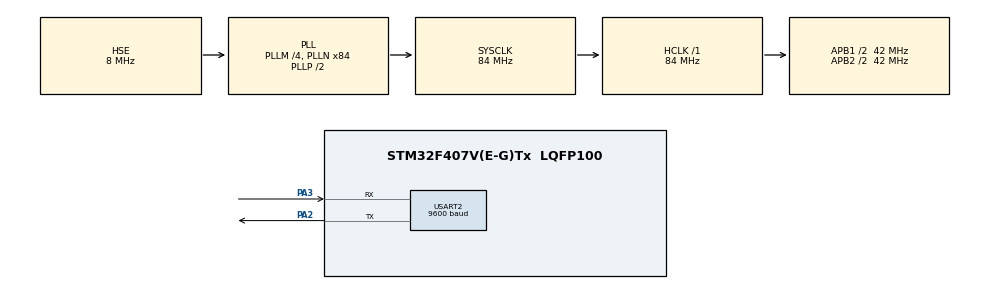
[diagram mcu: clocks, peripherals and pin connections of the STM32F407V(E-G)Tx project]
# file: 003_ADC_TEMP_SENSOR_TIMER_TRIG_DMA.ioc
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ADC1.Channel-0\#ChannelRegularConversion=ADC_CHANNEL_TEMPSENSOR
ADC1.Channel-4\#ChannelRegularConversion=ADC_CHANNEL_TEMPSENSOR
ADC1.Channel-5\#ChannelRegularConversion=ADC_CHANNEL_TEMPSENSOR
ADC1.ClockPrescaler=ADC_CLOCK_SYNC_PCLK_DIV8
ADC1.DMAContinuousRequests=ENABLE
ADC1.EOCSelection=ADC_EOC_SINGLE_CONV
ADC1.ExternalTrigConv=ADC_EXTERNALTRIGCONV_T8_TRGO
ADC1.InjNumberOfConversion=0
ADC1.NbrOfConversion=3
ADC1.NbrOfConversionFlag=1
ADC1.Rank-0\#ChannelRegularConversion=1
ADC1.Rank-4\#ChannelRegularConversion=2
ADC1.Rank-5\#ChannelRegularConversion=3
ADC1.SamplingTime-0\#ChannelRegularConversion=ADC_SAMPLETIME_480CYCLES
ADC1.SamplingTime-4\#ChannelRegularConversion=ADC_SAMPLETIME_480CYCLES
ADC1.SamplingTime-5\#ChannelRegularConversion=ADC_SAMPLETIME_480CYCLES
ADC1.master=1
Dma.ADC1.0.Direction=DMA_PERIPH_TO_MEMORY
Dma.ADC1.0.FIFOMode=DMA_FIFOMODE_DISABLE
Dma.ADC1.0.Instance=DMA2_Stream0
Dma.ADC1.0.MemDataAlignment=DMA_MDATAALIGN_HALFWORD
Dma.ADC1.0.MemInc=DMA_MINC_ENABLE
Dma.ADC1.0.Mode=DMA_CIRCULAR
Dma.ADC1.0.PeriphDataAlignment=DMA_PDATAALIGN_HALFWORD
Dma.ADC1.0.PeriphInc=DMA_PINC_DISABLE
Dma.ADC1.0.Priority=DMA_PRIORITY_LOW
Dma.Request0=ADC1
Mcu.Family=STM32F4
Mcu.Name=STM32F407V(E-G)Tx
Mcu.Package=LQFP100
NVIC.DMA2_Stream0_IRQn=true\:0\:0\:false\:false\:true\:false\:true
NVIC.PriorityGroup=NVIC_PRIORITYGROUP_0
NVIC.TIM8_UP_TIM13_IRQn=true\:0\:0\:false\:false\:true\:true\:true
PA2.Mode=Asynchronous
PA2.Signal=USART2_TX
PA3.Mode=Asynchronous
PA3.Signal=USART2_RX
PH0-OSC_IN.Mode=HSE-External-Oscillator
PH0-OSC_IN.Signal=RCC_OSC_IN
PH1-OSC_OUT.Mode=HSE-External-Oscillator
PH1-OSC_OUT.Signal=RCC_OSC_OUT
ProjectManager.HeapSize=0x200
ProjectManager.StackSize=0x400
ProjectManager.TargetToolchain=STM32CubeIDE
RCC.48MHZClocksFreq_Value=24000000
RCC.AHBFreq_Value=84000000
RCC.APB1CLKDivider=RCC_HCLK_DIV2
RCC.APB1Freq_Value=42000000
RCC.APB1TimFreq_Value=84000000
RCC.APB2CLKDivider=RCC_HCLK_DIV2
RCC.APB2Freq_Value=42000000
RCC.APB2TimFreq_Value=84000000
RCC.CortexFreq_Value=84000000
RCC.HCLKFreq_Value=84000000
RCC.HSE_VALUE=8000000
RCC.HSI_VALUE=16000000
RCC.PLLM=4
RCC.PLLN=84
RCC.PLLQ=7
RCC.PLLSourceVirtual=RCC_PLLSOURCE_HSE
RCC.SYSCLKFreq_VALUE=84000000
RCC.SYSCLKSource=RCC_SYSCLKSOURCE_PLLCLK
RCC.VCOOutputFreq_Value=168000000
TIM8.Period=1999
TIM8.Prescaler=41999
TIM8.TIM_MasterOutputTrigger=TIM_TRGO_UPDATE
TIM8.TIM_MasterSlaveMode=TIM_MASTERSLAVEMODE_ENABLE
USART2.BaudRate=9600
USART2.VirtualMode=VM_ASYNC
VP_ADC1_TempSens_Input.Mode=IN-TempSens
VP_TIM8_VS_ClockSourceINT.Mode=Internal
board=STM32F407G-DISC1

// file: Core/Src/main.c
/* USER CODE BEGIN Header */
/**
  ******************************************************************************
  * @file           : main.c
  * @brief          : Main program body
  ******************************************************************************
  * @attention
  *
  * Copyright (c) 2022 STMicroelectronics.
  * All rights reserved.
  *
  * This software is licensed under terms that can be found in the LICENSE file
  * in the root directory of this software component.
  * If no LICENSE file comes with this software, it is provided AS-IS.
  *
  ******************************************************************************
  */
/* USER CODE END Header */
#include "main.h"
#include <string.h>
#include <stdio.h>

ADC_HandleTypeDef hadc1;
DMA_HandleTypeDef hdma_adc1;

TIM_HandleTypeDef htim8;

UART_HandleTypeDef huart2;

/* USER CODE BEGIN PV */
volatile uint8_t convCompleted = 0;
uint16_t rawValues[3];
/* USER CODE END PV */

void SystemClock_Config(void);
static void MX_GPIO_Init(void);
static void MX_DMA_Init(void);
static void MX_ADC1_Init(void);
static void MX_TIM8_Init(void);
static void MX_USART2_UART_Init(void);

int main(void)
{
  /* USER CODE BEGIN 1 */
	char msg[35];

	  float temp;
  /* USER CODE END 1 */

  /* MCU Configuration--------------------------------------------------------*/

  /* Reset of all peripherals, Initializes the Flash interface and the Systick. */
  HAL_Init();

  /* Configure the system clock */
  SystemClock_Config();

  /* Initialize all configured peripherals */
  MX_GPIO_Init();
  MX_DMA_Init();
  MX_ADC1_Init();
  MX_TIM8_Init();
  MX_USART2_UART_Init();
  /* USER CODE BEGIN 2 */
  HAL_TIM_Base_Start(&htim8);
    HAL_ADC_Start_DMA(&hadc1, (uint32_t*)rawValues, 3);
  /* USER CODE END 2 */

  /* Infinite loop */
  while (1)
  {

    /* USER CODE BEGIN 3 */
	  while(!convCompleted)
	  {

	  }

	       for(uint8_t i = 0; i < hadc1.Init.NbrOfConversion; i++) {
	    	   temp = (((float)rawValues[i]) / 4095) * 3000;
	    	   	temp = ((temp - 760.0) / 2.5) + 25;

	        sprintf(msg, "rawValue %d: %hu\r\n", i, rawValues[i]);
	        HAL_UART_Transmit(&huart2, (uint8_t*) msg, strlen(msg), HAL_MAX_DELAY);

	        sprintf(msg, "Temperature %d: %.3f\r\n",i,  temp);
	        HAL_UART_Transmit(&huart2, (uint8_t*) msg, strlen(msg), HAL_MAX_DELAY);
	      }
	      convCompleted = 0;
  }
  /* USER CODE END 3 */
}

void SystemClock_Config(void)
{
  RCC_OscInitTypeDef RCC_OscInitStruct = {0};
  RCC_ClkInitTypeDef RCC_ClkInitStruct = {0};

  /** Configure the main internal regulator output voltage
  */
  __HAL_RCC_PWR_CLK_ENABLE();
  __HAL_PWR_VOLTAGESCALING_CONFIG(PWR_REGULATOR_VOLTAGE_SCALE1);
  /** Initializes the RCC Oscillators according to the specified parameters
  * in the RCC_OscInitTypeDef structure.
  */
  RCC_OscInitStruct.OscillatorType = RCC_OSCILLATORTYPE_HSE;
  RCC_OscInitStruct.HSEState = RCC_HSE_ON;
  RCC_OscInitStruct.PLL.PLLState = RCC_PLL_ON;
  RCC_OscInitStruct.PLL.PLLSource = RCC_PLLSOURCE_HSE;
  RCC_OscInitStruct.PLL.PLLM = 4;
  RCC_OscInitStruct.PLL.PLLN = 84;
  RCC_OscInitStruct.PLL.PLLP = RCC_PLLP_DIV2;
  RCC_OscInitStruct.PLL.PLLQ = 7;
  if (HAL_RCC_OscConfig(&RCC_OscInitStruct) != HAL_OK)
  {
    Error_Handler();
  }
  /** Initializes the CPU, AHB and APB buses clocks
  */
  RCC_ClkInitStruct.ClockType = RCC_CLOCKTYPE_HCLK|RCC_CLOCKTYPE_SYSCLK
                              |RCC_CLOCKTYPE_PCLK1|RCC_CLOCKTYPE_PCLK2;
  RCC_ClkInitStruct.SYSCLKSource = RCC_SYSCLKSOURCE_PLLCLK;
  RCC_ClkInitStruct.AHBCLKDivider = RCC_SYSCLK_DIV1;
  RCC_ClkInitStruct.APB1CLKDivider = RCC_HCLK_DIV2;
  RCC_ClkInitStruct.APB2CLKDivider = RCC_HCLK_DIV2;

  if (HAL_RCC_ClockConfig(&RCC_ClkInitStruct, FLASH_LATENCY_2) != HAL_OK)
  {
    Error_Handler();
  }
}

static void MX_ADC1_Init(void)
{

  ADC_ChannelConfTypeDef sConfig = {0};

  /** Configure the global features of the ADC (Clock, Resolution, Data Alignment and number of conversion)
  */
  hadc1.Instance = ADC1;
  hadc1.Init.ClockPrescaler = ADC_CLOCK_SYNC_PCLK_DIV8;
  hadc1.Init.Resolution = ADC_RESOLUTION_12B;
  hadc1.Init.ScanConvMode = ENABLE;
  hadc1.Init.ContinuousConvMode = DISABLE;
  hadc1.Init.DiscontinuousConvMode = DISABLE;
  hadc1.Init.ExternalTrigConvEdge = ADC_EXTERNALTRIGCONVEDGE_RISING;
  hadc1.Init.ExternalTrigConv = ADC_EXTERNALTRIGCONV_T8_TRGO;
  hadc1.Init.DataAlign = ADC_DATAALIGN_RIGHT;
  hadc1.Init.NbrOfConversion = 3;
  hadc1.Init.DMAContinuousRequests = ENABLE;
  hadc1.Init.EOCSelection = ADC_EOC_SINGLE_CONV;
  if (HAL_ADC_Init(&hadc1) != HAL_OK)
  {
    Error_Handler();
  }
  /** Configure for the selected ADC regular channel its corresponding rank in the sequencer and its sample time.
  */
  sConfig.Channel = ADC_CHANNEL_TEMPSENSOR;
  sConfig.Rank = 1;
  sConfig.SamplingTime = ADC_SAMPLETIME_480CYCLES;
  if (HAL_ADC_ConfigChannel(&hadc1, &sConfig) != HAL_OK)
  {
    Error_Handler();
  }
  /** Configure for the selected ADC regular channel its corresponding rank in the sequencer and its sample time.
  */
  sConfig.Rank = 2;
  if (HAL_ADC_ConfigChannel(&hadc1, &sConfig) != HAL_OK)
  {
    Error_Handler();
  }
  /** Configure for the selected ADC regular channel its corresponding rank in the sequencer and its sample time.
  */
  sConfig.Rank = 3;
  if (HAL_ADC_ConfigChannel(&hadc1, &sConfig) != HAL_OK)
  {
    Error_Handler();
  }

}

static void MX_TIM8_Init(void)
{

  TIM_ClockConfigTypeDef sClockSourceConfig = {0};
  TIM_MasterConfigTypeDef sMasterConfig = {0};

  htim8.Instance = TIM8;
  htim8.Init.Prescaler = 41999;
  htim8.Init.CounterMode = TIM_COUNTERMODE_UP;
  htim8.Init.Period = 1999;
  htim8.Init.ClockDivision = TIM_CLOCKDIVISION_DIV1;
  htim8.Init.RepetitionCounter = 0;
  htim8.Init.AutoReloadPreload = TIM_AUTORELOAD_PRELOAD_DISABLE;
  if (HAL_TIM_Base_Init(&htim8) != HAL_OK)
  {
    Error_Handler();
  }
  sClockSourceConfig.ClockSource = TIM_CLOCKSOURCE_INTERNAL;
  if (HAL_TIM_ConfigClockSource(&htim8, &sClockSourceConfig) != HAL_OK)
  {
    Error_Handler();
  }
  sMasterConfig.MasterOutputTrigger = TIM_TRGO_UPDATE;
  sMasterConfig.MasterSlaveMode = TIM_MASTERSLAVEMODE_ENABLE;
  if (HAL_TIMEx_MasterConfigSynchronization(&htim8, &sMasterConfig) != HAL_OK)
  {
    Error_Handler();
  }

}

static void MX_USART2_UART_Init(void)
{

  huart2.Instance = USART2;
  huart2.Init.BaudRate = 9600;
  huart2.Init.WordLength = UART_WORDLENGTH_8B;
  huart2.Init.StopBits = UART_STOPBITS_1;
  huart2.Init.Parity = UART_PARITY_NONE;
  huart2.Init.Mode = UART_MODE_TX_RX;
  huart2.Init.HwFlowCtl = UART_HWCONTROL_NONE;
  huart2.Init.OverSampling = UART_OVERSAMPLING_16;
  if (HAL_UART_Init(&huart2) != HAL_OK)
  {
    Error_Handler();
  }

}

static void MX_DMA_Init(void)
{

  /* DMA controller clock enable */
  __HAL_RCC_DMA2_CLK_ENABLE();

  /* DMA interrupt init */
  /* DMA2_Stream0_IRQn interrupt configuration */
  HAL_NVIC_SetPriority(DMA2_Stream0_IRQn, 0, 0);
  HAL_NVIC_EnableIRQ(DMA2_Stream0_IRQn);

}

static void MX_GPIO_Init(void)
{

  /* GPIO Ports Clock Enable */
  __HAL_RCC_GPIOH_CLK_ENABLE();
  __HAL_RCC_GPIOA_CLK_ENABLE();

}

/* USER CODE BEGIN 4 */
void HAL_ADC_ConvCpltCallback(ADC_HandleTypeDef* hadc) {
  convCompleted = 1;
}

void HAL_ADC_ErrorCallback(ADC_HandleTypeDef *hadc) {
  asm("BKPT #0");
}
/* USER CODE END 4 */

void Error_Handler(void)
{
  __disable_irq();
  while (1)
  {
  }
}
